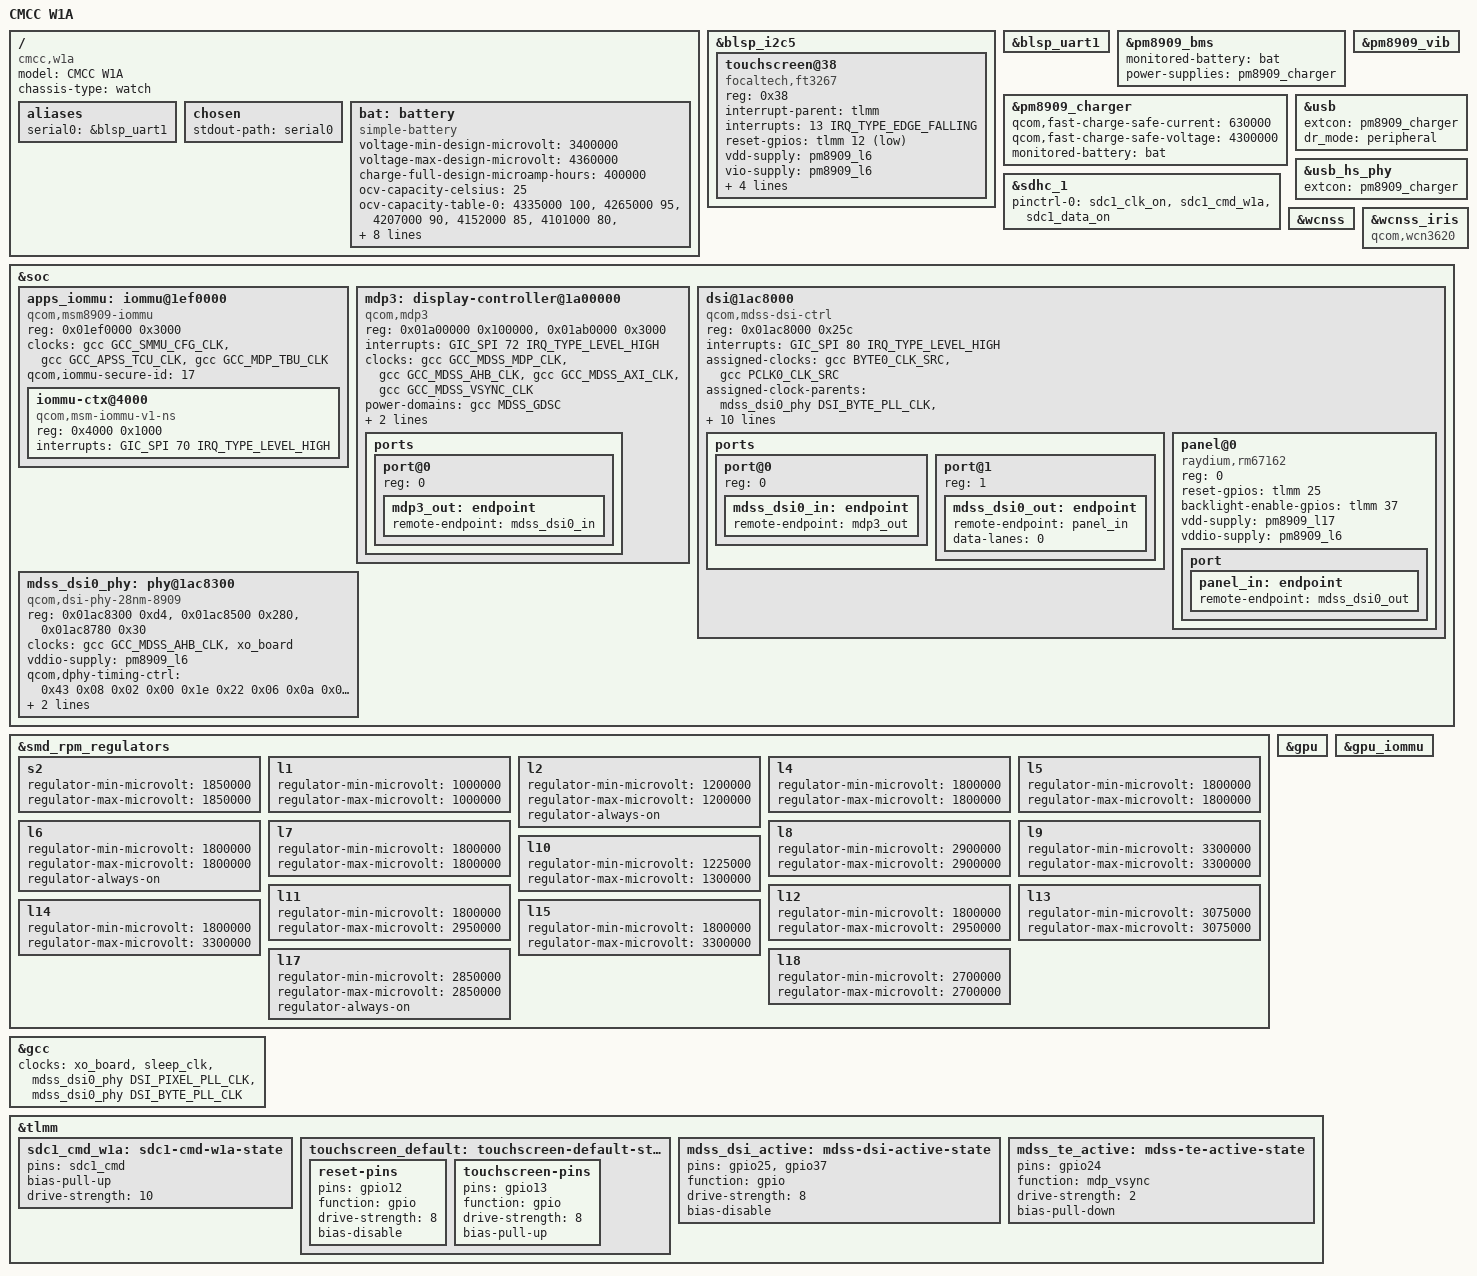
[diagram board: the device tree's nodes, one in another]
// SPDX-License-Identifier: GPL-2.0-only
/*
 * CMCC W1A kids locator watch
 *
 * SoC: Qualcomm MSM8909 (APQ8009-class), PMIC PM8916
 * Display: 400x400 round AMOLED (RM67162-class), DSI via MDP3
 * Touch: FocalTech FT3267 @ blsp_i2c5 0x38 (mainline driver missing, node
 *        kept for the bring-up driver port)
 * Storage: eMMC (userdata = "sdcard" p33, firmware p1)
 *
 * Reference: downstream 3.18 DTB (stock-dtbs/01.dtb), acer-t01 mainline port.
 */

/dts-v1/;

/* W1A m2s: lk2nd's last DSI command DMA buffer lives here (its splash
 * path is deterministic across boots).  Keep the page out of Linux's
 * allocator so the fetch probe can copy a packet to the exact address
 * lk2nd successfully fetched from. */
/memreserve/ 0x08f68f000 0x1000;

#include "qcom-msm8909-pm8909.dtsi"

#include <dt-bindings/gpio/gpio.h>
#include <dt-bindings/interrupt-controller/irq.h>
#include <dt-bindings/clock/qcom,dsi-phy-28nm.h>

/ {
	model = "CMCC W1A";
	compatible = "cmcc,w1a", "qcom,msm8909";
	chassis-type = "watch";

	aliases {
		serial0 = &blsp_uart1;
	};

	chosen {
		#address-cells = <1>;
		#size-cells = <1>;
		ranges;

		stdout-path = "serial0";

		/*
		 * No hand-written framebuffer node: lk2nd injects the real
		 * one (actual MDP3 format/stride/clocks) when booted with
		 * lk2nd.pass-simplefb=xrgb8888 on the cmdline.
		 */
	};

	/*
	 * No reserved-memory framebuffer@83000000: lk2nd injects the
	 * authoritative cont-splash node for the live framebuffer
	 * (0x83200000, 468 KiB) when booted with lk2nd.pass-simplefb.
	 * The old 12 MiB splash_region from downstream overlaps it and
	 * triggers "reserved mem: OVERLAP DETECTED" at boot.
	 */

	/*
	 * TODO: real battery characterization (downstream: 100k therm,
	 * vref 1.8V, vddmax 4.36V). Values provisional until BMS logs
	 * are captured under the mainline kernel.
	 */
	bat: battery {
		compatible = "simple-battery";
		voltage-min-design-microvolt = <3400000>;
		voltage-max-design-microvolt = <4360000>;
		charge-full-design-microamp-hours = <400000>;

		ocv-capacity-celsius = <25>;
		ocv-capacity-table-0 = <4335000 100>, <4265000 95>,
			<4207000 90>, <4152000 85>, <4101000 80>, <4051000 75>,
			<3995000 70>, <3958000 65>, <3921000 60>, <3874000 55>,
			<3838000 50>, <3815000 45>, <3797000 40>, <3783000 35>,
			<3772000 30>, <3763000 25>, <3744000 20>, <3718000 16>,
			<3692000 13>, <3689000 11>, <3688000 10>, <3687000 9>,
			<3685000 8>, <3683000 7>, <3679000 6>, <3663000 5>,
			<3620000 4>, <3555000 3>, <3461000 2>, <3312000 1>,
			<3000000 0>;
	};
};

/* FocalTech FT3267 touch: downstream irq gpio13 active, reset gpio12,
 * vdd/vcc_i2c = 8916_l6 (1.8V fixed), avdd = 8916_l17 (2.85V always-on).
 * No mainline driver yet; node is inert until the port lands.
 */
&blsp_i2c5 {
	status = "okay";

	touchscreen@38 {
		compatible = "focaltech,ft3267";
		reg = <0x38>;

		interrupt-parent = <&tlmm>;
		interrupts = <13 IRQ_TYPE_EDGE_FALLING>;

		reset-gpios = <&tlmm 12 GPIO_ACTIVE_LOW>;

		vdd-supply = <&pm8909_l6>;
		vio-supply = <&pm8909_l6>;
		avdd-supply = <&pm8909_l17>;

		touchscreen-size-x = <400>;
		touchscreen-size-y = <400>;

		pinctrl-0 = <&touchscreen_default>;
		pinctrl-names = "default";
	};
};

&blsp_uart1 {
	status = "okay";
};

&pm8909_bms {
	monitored-battery = <&bat>;
	power-supplies = <&pm8909_charger>;
	status = "okay";
};

&pm8909_charger {
	qcom,fast-charge-safe-current = <630000>;
	qcom,fast-charge-safe-voltage = <4300000>;

	monitored-battery = <&bat>;

	status = "okay";
};

&pm8909_vib {
	status = "okay";
};

&sdhc_1 {
	/* CMD with internal pull-up (see tlmm/sdc1_cmd_w1a) */
	pinctrl-0 = <&sdc1_clk_on &sdc1_cmd_w1a &sdc1_data_on>;
	status = "okay";
};

/*
 * USB: peripheral-only so ci-hdrc always runs the gadget (no ID-pin
 * dependency). extcon = pm8909_charger: the pm8916 LBC driver holds the
 * usbin VBUS IRQ and exposes EXTCON_USB. Do NOT enable pm8909_usbin
 * (extcon-pm8941-misc) alongside the charger - both request the same
 * IRQ and the second prober hard-fails with -EBUSY, leaving any USB
 * node referencing it deferred forever (seen on boot #5).
 */
&usb {
	extcon = <&pm8909_charger>;
	dr_mode = "peripheral";
	status = "okay";
};

&usb_hs_phy {
	extcon = <&pm8909_charger>;
	status = "okay";
};

&wcnss {
	status = "okay";
};

&wcnss_iris {
	compatible = "qcom,wcn3620";
};

/*
 * Display bring-up (B-full step 1: DSI host + PHY + panel).
 *
 * MDP3 (display-controller@1a00000) has no mainline driver yet; it stays
 * driven by the lk2nd-programmed state (12 fps autorefresh) until the
 * MDP3 KMS driver lands. These nodes wire the DSI controller (ctrl
 * @0x1ac8000, GIC 80), its 28nm-lp PHY (pll @0x1ac8300, phy @0x1ac8500,
 * regulator @0x1ac8780 - same register layout as msm8916, different
 * addresses) and the RM67162 panel so their drivers can probe.
 *
 * Register data from the downstream 3.18 DTB (stock-dtbs/01.dtb):
 * mdss_dsi_ctrl0@1ac8000, qcom,mdss_dsi_pll@1ac8300, rm67162_wqvga_cmd.
 */

/*
 * Apps SMMU (B-full step 2: MDP3 KMS).  Like the GPU SMMU this is an
 * msm8916-class QSMMU v1, not smmu-v2: the downstream 3.18 DTB
 * declares apps_iommu with reg <0x1e00000 0x40000> + smmu_local_base
 * 0x1ef0000, and the context banks sit at 0x1e20000+ with the same
 * layout as 8916 (vfe@1e23000, mdp_0@1e24000, venus_ns@1e25000).
 * Wire it like upstream msm8916.dtsi: global regs at 0x1ef0000, ctx
 * range at 0x1e20000, secure id 17.  Only the MDP_0 context (non-
 * secure, SID 0xc00 -> asid 4) is described; msm GEM scanout needs
 * exactly that one.
 */
&soc {
	apps_iommu: iommu@1ef0000 {
		#address-cells = <1>;
		#size-cells = <1>;
		#iommu-cells = <1>;
		compatible = "qcom,msm8909-iommu", "qcom,msm-iommu-v1";
		ranges = <0 0x01e20000 0x20000>;
		reg = <0x01ef0000 0x3000>;
		/*
		 * m2u: "tbu" is qcom_iommu's optional third clock, bulk-enabled
		 * whenever the SMMU is resumed (attach).  The MDP TBU is the
		 * translation buffer unit every MDSS-port AXI read must cross
		 * once qcom_scm_restore_sec_cfg switches the port from bypass
		 * to CB4 translation - nothing else under mainline ever votes
		 * it (APCS 0x4500c BIT(4)); downstream's SMMU-v2 driver votes
		 * it, lk2nd never did (bypass mode).  A fetch hitting a
		 * clock-gated TBU hangs with no fault latched - matches the
		 * m2n-m2t evidence exactly (both engines, FSR clean).
		 */
		clocks = <&gcc GCC_SMMU_CFG_CLK>,
			 <&gcc GCC_APSS_TCU_CLK>,
			 <&gcc GCC_MDP_TBU_CLK>;
		clock-names = "iface", "bus", "tbu";
		qcom,iommu-secure-id = <17>;

		/* MDP_0 (downstream ctx@1e24000, SID 0xc00 -> asid 4) */
		iommu-ctx@4000 {
			compatible = "qcom,msm-iommu-v1-ns";
			reg = <0x4000 0x1000>;
			interrupts = <GIC_SPI 70 IRQ_TYPE_LEVEL_HIGH>;
		};
	};

	/*
	 * MDP3 display pipeline (B-full step 2): the single DMA_P fetch
	 * pipe feeding DSI command mode.  reg/irq/clock names follow the
	 * downstream mdss dtsi node (mdp_phys 0x1a00000+0x100000 incl.
	 * the DMA_P block @0x90000, vbif 0x1ab0000, GIC 72, iface/bus/
	 * core_src/core/vsync + gdsc_mdss).  Port 0 is the DSI input the
	 * msm drm component graph walks.
	 */
	mdp3: display-controller@1a00000 {
		compatible = "qcom,mdp3";
		reg = <0x01a00000 0x100000>,
		      <0x01ab0000 0x3000>;
		reg-names = "core", "vbif";
		interrupts = <GIC_SPI 72 IRQ_TYPE_LEVEL_HIGH>;

		clocks = <&gcc GCC_MDSS_MDP_CLK>,
			 <&gcc GCC_MDSS_AHB_CLK>,
			 <&gcc GCC_MDSS_AXI_CLK>,
			 <&gcc GCC_MDSS_VSYNC_CLK>;
		clock-names = "core_clk", "iface_clk", "bus_clk", "vsync_clk";

		power-domains = <&gcc MDSS_GDSC>;

		iommus = <&apps_iommu 4>;

		/* m3g: mux the panel TE pin (gpio24) to the MDP3 tear-check
		 * block's vsync input - SYNC_PRIMARY_LINE is the continuous
		 * vblank source for command mode */
		pinctrl-0 = <&mdss_te_active>;
		pinctrl-names = "default";

		ports {
			#address-cells = <1>;
			#size-cells = <0>;

			port@0 {
				reg = <0>;

				mdp3_out: endpoint {
					remote-endpoint = <&mdss_dsi0_in>;
				};
			};
		};
	};

	dsi@1ac8000 {
		compatible = "qcom,mdss-dsi-ctrl";
		reg = <0x01ac8000 0x25c>;
		reg-names = "dsi_ctrl";
		interrupts = <GIC_SPI 80 IRQ_TYPE_LEVEL_HIGH>;

		assigned-clocks = <&gcc BYTE0_CLK_SRC>,
				  <&gcc PCLK0_CLK_SRC>;
		assigned-clock-parents = <&mdss_dsi0_phy DSI_BYTE_PLL_CLK>,
					 <&mdss_dsi0_phy DSI_PIXEL_PLL_CLK>;

		clocks = <&gcc GCC_MDSS_MDP_CLK>,
			 <&gcc GCC_MDSS_AHB_CLK>,
			 <&gcc GCC_MDSS_AXI_CLK>,
			 <&gcc GCC_MDSS_BYTE0_CLK>,
			 <&gcc GCC_MDSS_PCLK0_CLK>,
			 <&gcc GCC_MDSS_ESC0_CLK>;
		clock-names = "mdp_core",
			      "iface",
			      "bus",
			      "byte",
			      "pixel",
			      "core";

		vdda-supply = <&pm8909_l2>;
		vddio-supply = <&pm8909_l6>;

		phys = <&mdss_dsi0_phy>;

		#address-cells = <1>;
		#size-cells = <0>;

		pinctrl-0 = <&mdss_dsi_active>;
		pinctrl-names = "default";

		ports {
			#address-cells = <1>;
			#size-cells = <0>;

			/* MDP3 -> DSI (command mode input) */
			port@0 {
				reg = <0>;

				mdss_dsi0_in: endpoint {
					remote-endpoint = <&mdp3_out>;
				};
			};

			port@1 {
				reg = <1>;

				mdss_dsi0_out: endpoint {
					remote-endpoint = <&panel_in>;
					/* single data lane, no lane swap (lane_map_0123) */
					data-lanes = <0>;
				};
			};
		};

		panel@0 {
			compatible = "raydium,rm67162";
			reg = <0>;

			reset-gpios = <&tlmm 25 GPIO_ACTIVE_HIGH>;
			backlight-enable-gpios = <&tlmm 37 GPIO_ACTIVE_HIGH>;

			vdd-supply = <&pm8909_l17>;
			vddio-supply = <&pm8909_l6>;

			port {
				panel_in: endpoint {
					remote-endpoint = <&mdss_dsi0_out>;
				};
			};
		};
	};

	mdss_dsi0_phy: phy@1ac8300 {
		compatible = "qcom,dsi-phy-28nm-8909";
		reg = <0x01ac8300 0xd4>,
		      <0x01ac8500 0x280>,
		      <0x01ac8780 0x30>;
		reg-names = "dsi_pll",
			    "dsi_phy",
			    "dsi_phy_regulator";

		#clock-cells = <1>;
		#phy-cells = <0>;

		clocks = <&gcc GCC_MDSS_AHB_CLK>,
			 <&xo_board>;
		clock-names = "iface", "ref";

		vddio-supply = <&pm8909_l6>;

		/*
		 * DPHY timing from the vendor panel file
		 * (lk2nd lk_panel_rm67162_wqvga_cmd.h): raw
		 * TIMING_CTRL_0..11 register values plus T_CLK_PRE /
		 * T_CLK_POST for the DSI CLKOUT_TIMING_CTRL register.
		 * The msm_dsi_dphy_timing_calc() values are 2-6x larger
		 * and keep the DSI link dead on this panel.
		 */
		qcom,dphy-timing-ctrl = /bits/ 32 <0x43 0x08 0x02 0x00
					     0x1e 0x22 0x06 0x0a
					     0x03 0x03 0x04 0x00>;
		qcom,dphy-clk-pre = <0x10>;
		qcom,dphy-clk-post = <0x07>;
	};
};

&smd_rpm_regulators {
	/*
	 * Voltage ranges from the downstream 3.18 DTB (stock-dtbs/01.dtb,
	 * rpm-regulator-ldoa*). The dtsi leaves every rpm regulator as an
	 * empty node {}: without board-level min/max the regulator core
	 * rejects every voltage change ("voltage operation not allowed"),
	 * which killed eMMC (vmmc = l8) and the USB HS phy (l7/l13) on
	 * the first mainline boots.
	 */
	s2 {
		/* unused on W1A (downstream: disabled) */
		regulator-min-microvolt = <1850000>;
		regulator-max-microvolt = <1850000>;
	};

	l1 {
		regulator-min-microvolt = <1000000>;
		regulator-max-microvolt = <1000000>;
	};

	/* DSI PHY vdda (1.2V): downstream mdss_dsi vdda-supply = 8916_l2.
	 * Mainline has no DSI node, so nothing holds a reference and the
	 * regulator late cleanup disables it ~1.9s into boot - the DSI link
	 * dies and the panel freezes on its last GRAM image (lk2nd UI). This
	 * is what broke the screen starting at boot #9: before the l8 fix the
	 * rpm regulator requests all failed, so l2 simply kept whatever state
	 * lk2nd had left (on). Keep it on until a real MDP3/DSI driver owns
	 * this rail. Same rationale as l6/l17.
	 */
	l2 {
		regulator-min-microvolt = <1200000>;
		regulator-max-microvolt = <1200000>;
		regulator-always-on;
	};

	l4 {
		regulator-min-microvolt = <1800000>;
		regulator-max-microvolt = <1800000>;
	};

	/* vqmmc for eMMC (HS200 1.8V signaling) */
	l5 {
		regulator-min-microvolt = <1800000>;
		regulator-max-microvolt = <1800000>;
	};

	/* touch + wcnss iris rails: always-on downstream */
	l6 {
		regulator-min-microvolt = <1800000>;
		regulator-max-microvolt = <1800000>;
		regulator-always-on;
	};

	/* USB HS phy v1p8 */
	l7 {
		regulator-min-microvolt = <1800000>;
		regulator-max-microvolt = <1800000>;
	};

	/* vmmc for eMMC (downstream: fixed 2.9V) */
	l8 {
		regulator-min-microvolt = <2900000>;
		regulator-max-microvolt = <2900000>;
	};

	l9 {
		regulator-min-microvolt = <3300000>;
		regulator-max-microvolt = <3300000>;
	};

	/* wcnss iris vddrfa: mainline iris driver requests fixed 1.3V
	 * (qcom_wcnss_iris.c vddrfa 1300000-1300000). Downstream 3.18 ran
	 * l10 at 2.7-2.8V for its own driver - that range makes the
	 * mainline request fail with "unsupportable voltage range".
	 */
	l10 {
		regulator-min-microvolt = <1225000>;
		regulator-max-microvolt = <1300000>;
	};

	l11 {
		regulator-min-microvolt = <1800000>;
		regulator-max-microvolt = <2950000>;
	};

	l12 {
		regulator-min-microvolt = <1800000>;
		regulator-max-microvolt = <2950000>;
	};

	/* USB HS phy v3p3 */
	l13 {
		regulator-min-microvolt = <3075000>;
		regulator-max-microvolt = <3075000>;
	};

	l14 {
		regulator-min-microvolt = <1800000>;
		regulator-max-microvolt = <3300000>;
	};

	l15 {
		regulator-min-microvolt = <1800000>;
		regulator-max-microvolt = <3300000>;
	};

	/* wcnss iris avdd, always-on downstream */
	l17 {
		regulator-min-microvolt = <2850000>;
		regulator-max-microvolt = <2850000>;
		regulator-always-on;
	};

	l18 {
		regulator-min-microvolt = <2700000>;
		regulator-max-microvolt = <2700000>;
	};
};

&gpu {
	status = "okay";
};

&gpu_iommu {
	status = "okay";
};

&gcc {
	/*
	 * lk2nd brings the panel up (MDP3 + DSI + RM67162, command mode)
	 * before jumping to the kernel and injects the simplefb node.
	 *
	 * The DSI PLL clocks from the PHY feed gcc's dsi0pll/dsi0pllbyte
	 * inputs (the dtsi leaves them as <0> placeholders), so that
	 * byte0/pclk0 clk_src can be reparented to the PHY PLLs.
	 */
	clocks = <&xo_board>, <&sleep_clk>,
		 <&mdss_dsi0_phy DSI_PIXEL_PLL_CLK>,
		 <&mdss_dsi0_phy DSI_BYTE_PLL_CLK>;
	clock-names = "xo", "sleep_clk", "dsi0pll", "dsi0pllbyte";

	/*
	 * MDSS clocks were previously all protected (unregistered) so the
	 * clk framework could not gate off what lk2nd programmed while
	 * nothing claimed them.  Everything MDSS is now owned by drivers;
	 * clk_ignore_unused on the cmdline still guards the lk2nd state.
	 *
	 * m2t: GCC_MDP_TBU_CLK UN-protected (registered, still unclaimed):
	 * the m2s probe showed MDSS fetches hang with NO SMMU fault latched
	 * (CB4 enabled, TTBR0 valid, FSR clean) - consistent with the fetch
	 * dying inside a clock-gated MDP TBU after qcom_iommu's
	 * restore_sec_cfg switched the MDSS port from bypass to CB4
	 * translation.  Registering it lets the dsi_host fetch probe read
	 * and vote on it (APCS 0x4500c BIT(4)) through the clk framework.
	 */
};

&tlmm {
	/*
	 * eMMC CMD line: stock DTB drives sdc1_cmd with bias-pull-up; the
	 * dtsi default (bias-disable) leaves CMD floating - W1A has no
	 * external pull on the eMMC bus and mmc0 fails card init with no
	 * response ("Failed to initialize a non-removable card").
	 */
	sdc1_cmd_w1a: sdc1-cmd-w1a-state {
		pins = "sdc1_cmd";
		bias-pull-up;
		drive-strength = <10>;
	};

	touchscreen_default: touchscreen-default-state {
		reset-pins {
			pins = "gpio12";
			function = "gpio";
			drive-strength = <8>;
			bias-disable;
		};

		touchscreen-pins {
			pins = "gpio13";
			function = "gpio";
			drive-strength = <8>;
			bias-pull-up;
		};
	};

	/* DSI panel reset (gpio25) + backlight enable (gpio37):
	 * stock mdss_dsi_active drives both high at 8mA.
	 */
	mdss_dsi_active: mdss-dsi-active-state {
		pins = "gpio25", "gpio37";
		function = "gpio";
		drive-strength = <8>;
		bias-disable;
	};

	/* Panel TE -> MDP3 vsync: routed to the mdp_vsync function
	 * (stock pmx_mdss_te), used by the MDP3 tear-check once that
	 * driver lands.
	 */
	mdss_te_active: mdss-te-active-state {
		pins = "gpio24";
		function = "mdp_vsync";
		drive-strength = <2>;
		bias-pull-down;
	};
};
